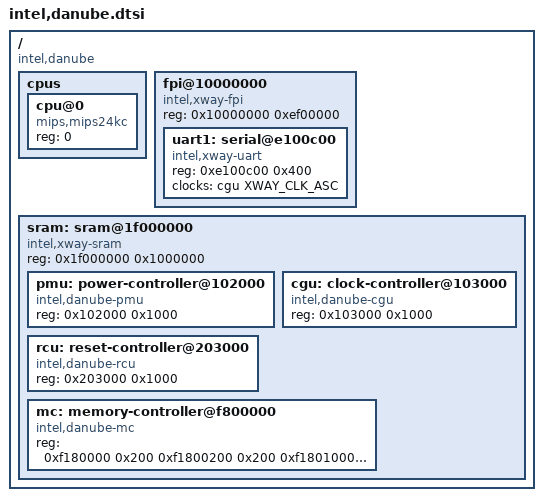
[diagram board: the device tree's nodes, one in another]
// SPDX-License-Identifier: GPL-2.0+
/*
 * Copyright (C) 2016-2020 Daniel Schwierzeck, daniel.schwierzeck@gmail.com
 */

#include <dt-bindings/clock/intel,xway.h>
#include "skeleton.dtsi"

/ {
	compatible = "intel,danube";

	cpus {
		#address-cells = <1>;
		#size-cells = <0>;

		cpu@0 {
			reg = <0>;
			compatible = "mips,mips24kc";
		};
	};

	fpi@10000000 {
		#address-cells = <1>;
		#size-cells = <1>;
		compatible = "intel,xway-fpi", "simple-bus";
		reg = <0x10000000 0xef00000>;
		ranges = <0x0 0x10000000 0xeefffff>;

		uart1: serial@e100c00 {
			compatible = "intel,xway-uart";
			reg = <0xe100c00 0x400>;
			clocks = <&cgu XWAY_CLK_ASC>;
			clock-names = "asc";
		};
	};

	sram: sram@1f000000 {
		#address-cells = <1>;
		#size-cells = <1>;
		compatible = "intel,xway-sram", "simple-bus";
		reg = <0x1f000000 0x1000000>;
		ranges = <0x0 0x1f000000 0xffffff>;

		pmu: power-controller@102000 {
			compatible = "intel,danube-pmu";
			reg = <0x102000 0x1000>;
		};

		cgu: clock-controller@103000 {
			compatible = "intel,danube-cgu";
			reg = <0x103000 0x1000>;
			#clock-cells = <1>;
		};

		rcu: reset-controller@203000 {
			compatible = "intel,danube-rcu";
			reg = <0x203000 0x1000>;
		};

		mc: memory-controller@f800000 {
			compatible = "intel,danube-mc";
			reg = <0xf180000 0x200
				0xf1800200 0x200
				0xf1801000 0x200>;
		};
	};
};
